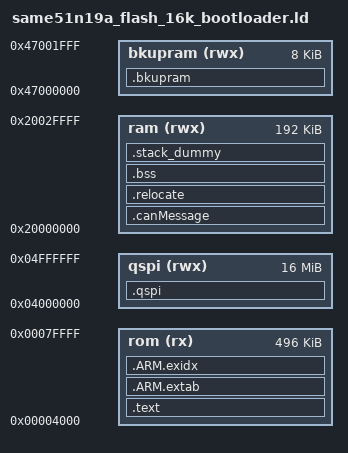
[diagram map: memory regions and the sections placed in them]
/**
 * \file
 *
 * \brief Linker script for running in internal FLASH on the SAME51N19A
 *
 * Copyright (c) 2019 Microchip Technology Inc.
 *
 * \asf_license_start
 *
 * \page License
 *
 * SPDX-License-Identifier: Apache-2.0
 *
 * Licensed under the Apache License, Version 2.0 (the "License"); you may
 * not use this file except in compliance with the License.
 * You may obtain a copy of the Licence at
 * 
 * http://www.apache.org/licenses/LICENSE-2.0
 * 
 * Unless required by applicable law or agreed to in writing, software
 * distributed under the License is distributed on an AS IS BASIS, WITHOUT
 * WARRANTIES OR CONDITIONS OF ANY KIND, either express or implied.
 * See the License for the specific language governing permissions and
 * limitations under the License.
 *
 * \asf_license_stop
 *
 */


OUTPUT_FORMAT("elf32-littlearm", "elf32-littlearm", "elf32-littlearm")
OUTPUT_ARCH(arm)
SEARCH_DIR(.)

/* Memory Spaces Definitions */
MEMORY
{
  rom      (rx)  : ORIGIN = 0x00004000, LENGTH = 0x0007c000
  ram      (rwx) : ORIGIN = 0x20000000, LENGTH = 0x00030000
  bkupram  (rwx) : ORIGIN = 0x47000000, LENGTH = 0x00002000
  qspi     (rwx) : ORIGIN = 0x04000000, LENGTH = 0x01000000
}

/* Section Definitions */
SECTIONS
{
    .text :
    {
        . = ALIGN(4);
        _sfixed = .;
        KEEP(*(.vectors .vectors.*))
        *(.text .text.* .gnu.linkonce.t.*)
        *(.glue_7t) *(.glue_7)
        *(.rodata .rodata* .gnu.linkonce.r.*)
 
        /* Support C constructors, and C destructors in both user code
           and the C library. This also provides support for C++ code. */
        . = ALIGN(4);
        KEEP(*(.init))
        . = ALIGN(4);
        __preinit_array_start = .;
        KEEP (*(.preinit_array))
        __preinit_array_end = .;

        . = ALIGN(4);
        __init_array_start = .;
        KEEP (*(SORT(.init_array.*)))
        KEEP (*(.init_array))
        __init_array_end = .;

        . = ALIGN(4);
        KEEP (*crtbegin.o(.ctors))
        KEEP (*(EXCLUDE_FILE (*crtend.o) .ctors))
        KEEP (*(SORT(.ctors.*)))
        KEEP (*crtend.o(.ctors))

        . = ALIGN(4);
        KEEP(*(.fini))

        . = ALIGN(4);
        __fini_array_start = .;
        KEEP (*(.fini_array))
        KEEP (*(SORT(.fini_array.*)))
        __fini_array_end = .;

        KEEP (*crtbegin.o(.dtors))
        KEEP (*(EXCLUDE_FILE (*crtend.o) .dtors))
        KEEP (*(SORT(.dtors.*)))
        KEEP (*crtend.o(.dtors))

        . = ALIGN(4);
        _efixed = .;            /* End of text section */
    } > rom

    .ARM.extab :
    {
        *(.ARM.extab* .gnu.linkonce.armextab.*)
    } > rom

    /* .ARM.exidx is sorted, so has to go in its own output section.  */
    PROVIDE_HIDDEN (__exidx_start = .);
    .ARM.exidx :
    {
      *(.ARM.exidx* .gnu.linkonce.armexidx.*)
    } > rom
    PROVIDE_HIDDEN (__exidx_end = .);

    . = ALIGN(4);
    _etext = .;

	/* CAN message buffers must be in the first 64K of RAM */
    .canMessage (NOLOAD) :
    {
        . = ALIGN(4);
        _sCanMessage = . ;
		*(.CanMessage .CanMessage.*)
        . = ALIGN(4);
        _eCanMessage = . ;
    } > ram

    .relocate : AT (_etext)
    {
        . = ALIGN(4);
        _srelocate = .;
        *(.ramfunc .ramfunc.*);
        *(.data .data.*);
        . = ALIGN(4);
        _erelocate = .;
    } > ram

	_firmware_end = _etext + (_erelocate - _srelocate);		/* Embedded files start here */
	_firmware_crc = _firmware_end;							/* We append the CRC32 to the binary file. This is its offset in memory if we don't append embedded files */

    /* .bss section which is used for uninitialized data */
    .bss ALIGN(16) (NOLOAD) :
    {
        _sbss = . ;
        _szero = .;
        *(.bss .bss.*)
        *(COMMON)
        . = ALIGN(4);
        _ebss = . ;
        _ezero = .;
    } > ram

    . = ALIGN(4);
    _end = . ;

    /* .stack_dummy section doesn't contains any symbols. It is only
       used for linker to calculate size of stack sections, and assign
       values to stack symbols later */
    .stack_dummy :
    {
        *(.stack*)
    } > ram

    .bkupram (NOLOAD):
    {
        . = ALIGN(8);
        _sbkupram = .;
        *(.bkupram .bkupram.*);
        . = ALIGN(8);
        _ebkupram = .;
    } > bkupram

    .qspi (NOLOAD):
    {
        . = ALIGN(8);
        _sqspi = .;
        *(.qspi .qspi.*);
        . = ALIGN(8);
        _eqspi = .;
    } > qspi

    /* Set stack top to end of ram, and stack limit move down by
     * size of stack_dummy section */
    __StackTop = ORIGIN(ram) + LENGTH(ram);
    __StackLimit = __StackTop - SIZEOF(.stack_dummy);
    PROVIDE(_sstack = __StackLimit);
    PROVIDE(_estack = __StackTop);
}
